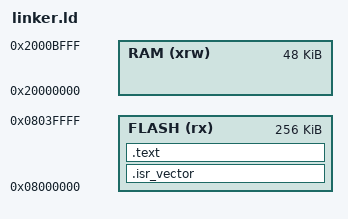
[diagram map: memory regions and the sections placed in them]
/* 建议的 linker.ld 结构 */
MEMORY 
{
    FLASH (rx) : ORIGIN = 0x08000000, LENGTH = 256K
    RAM (xrw)  : ORIGIN = 0x20000000, LENGTH = 48K
}

_estack = ORIGIN(RAM) + LENGTH(RAM);

SECTIONS 
{
    .isr_vector : 
    {
        . = ALIGN(4);
        KEEP(*(.isr_vector))
        . = ALIGN(4);
    } > FLASH

    /* 如果你注释掉了 .text，链接器可能会因为没有任何段进入 FLASH 而报错 */
    .text :
    {
        . = ALIGN(4);
        *(.text*)
        *(.rodata*)
        . = ALIGN(4);
    } > FLASH
}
